# AT32UC3L064 device description
Architecture: AVR32_UC3; Family: AVR UC3
Registers are 32-bit, read-write, reset 0x0 unless marked. A register's access mark holds for its fields unless they carry their own. Offsets are from the block's base; [hi:lo] are bit positions; lines under a group give offsets from that group; {n}, {i} and the like mark numbered series; 'fields as' and 'values as' point back to an identical list.

## SAU_HSB — Secure Access Unit
{0x0+4i} RTR[{i}] (i=0..15) access not given reset not defined
  [31:0] RTR — Remap Target Address for channel n
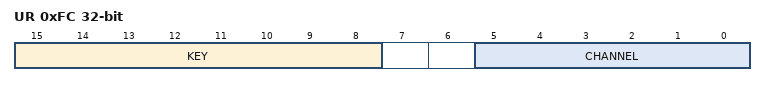
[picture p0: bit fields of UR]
0xFC UR wo reset not defined — Unlock Register
  [15:8] KEY — Unlock Key
  [5:0] CHANNEL — Channel number to unlock

## TWIM — Two-wire Master Interface
Instances: TWIM0 0xffff4400, TWIM1 0xffff4800
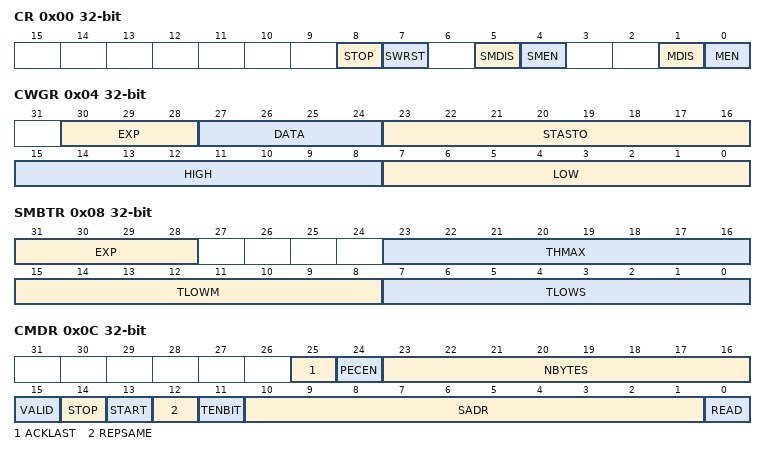
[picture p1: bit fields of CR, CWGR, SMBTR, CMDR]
0x00 CR wo
  [8] STOP, [7] SWRST, [5] SMDIS, [4] SMEN, [1] MDIS, [0] MEN
0x04 CWGR — Clock Waveform Generator
  [30:28] EXP, [27:24] DATA, [23:16] STASTO, [15:8] HIGH, [7:0] LOW
0x08 SMBTR — SMBus Time Out
  [31:28] EXP, [23:16] THMAX, [15:8] TLOWM, [7:0] TLOWS
0x0C CMDR — Command
  [25] ACKLAST, [24] PECEN, [23:16] NBYTES, [15] VALID, [14] STOP, [13] START, [12] REPSAME, [11] TENBIT, [10:1] SADR, [0] READ
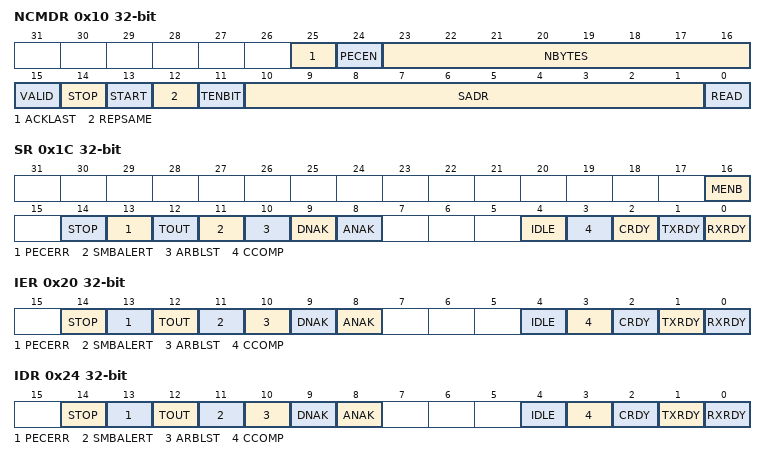
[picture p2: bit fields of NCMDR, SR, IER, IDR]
0x10 NCMDR — Next Command
  fields as CMDR
0x14 RHR ro — Receive Holding Registre
  [7:0] RXDATA
0x18 THR wo — Transmit Holding Register
  [7:0] TXDATA
0x1C SR ro — Status Register
  [16] MENB, [14] STOP, [13] PECERR, [12] TOUT, [11] SMBALERT, [10] ARBLST, [9] DNAK, [8] ANAK, [4] IDLE, [3] CCOMP, [2] CRDY, [1] TXRDY, [0] RXRDY
0x20 IER wo — Interrupt Enable Register
  [14] STOP, [13] PECERR, [12] TOUT, [11] SMBALERT, [10] ARBLST, [9] DNAK, [8] ANAK, [4] IDLE, [3] CCOMP, [2] CRDY, [1] TXRDY, [0] RXRDY
0x24 IDR wo — Interrupt Disable Register
  fields as IER
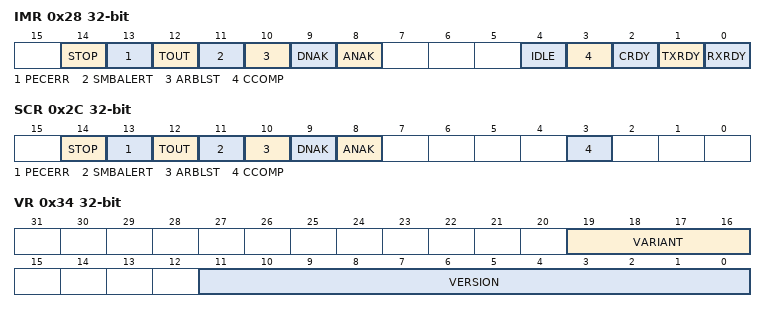
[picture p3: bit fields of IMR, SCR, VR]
0x28 IMR ro — Interrupt Mask Register
  fields as IER
0x2C SCR wo — Status Clear Register
  [14] STOP, [13] PECERR, [12] TOUT, [11] SMBALERT, [10] ARBLST, [9] DNAK, [8] ANAK, [3] CCOMP
0x30 PR ro — Parameter Register
0x34 VR ro — Version Register
  [19:16] VARIANT, [11:0] VERSION

## TWIS — Two-wire Slave Interface
Instances: TWIS0 0xffff4c00, TWIS1 0xffff5000
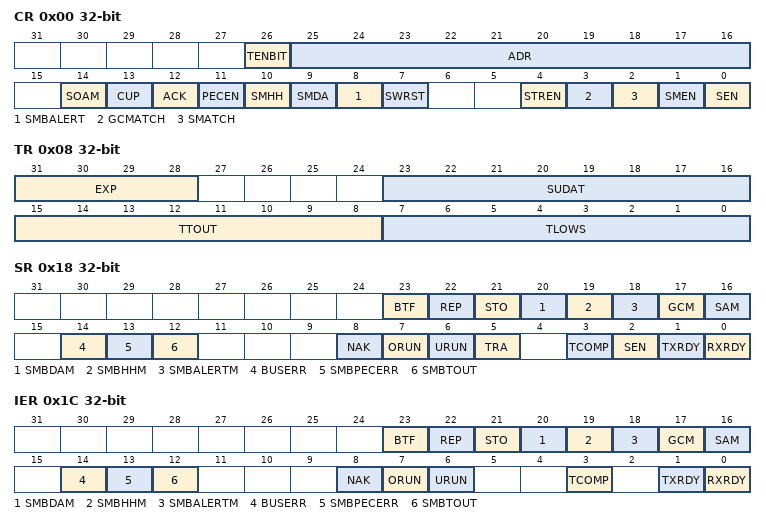
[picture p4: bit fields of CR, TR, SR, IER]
0x00 CR — Control Register
  [26] TENBIT, [25:16] ADR, [14] SOAM, [13] CUP, [12] ACK, [11] PECEN, [10] SMHH, [9] SMDA, [8] SMBALERT, [7] SWRST, [4] STREN, [3] GCMATCH, [2] SMATCH, [1] SMEN, [0] SEN
0x04 NBYTES
  [7:0] NBYTES
0x08 TR — Timing Register
  [31:28] EXP, [23:16] SUDAT, [15:8] TTOUT, [7:0] TLOWS
0x0C RHR ro — Receive Holding Registre
  [7:0] RXDATA
0x10 THR wo — Transmit Holding Register
  [7:0] TXDATA
0x14 PECR ro — Packet Error Check Register
  [7:0] PEC
0x18 SR ro — Status Register
  [23] BTF, [22] REP, [21] STO, [20] SMBDAM, [19] SMBHHM, [18] SMBALERTM, [17] GCM, [16] SAM, [14] BUSERR, [13] SMBPECERR, [12] SMBTOUT, [8] NAK, [7] ORUN, [6] URUN, [5] TRA, [3] TCOMP, [2] SEN, [1] TXRDY, [0] RXRDY
0x1C IER wo — Interrupt Enable Register
  [23] BTF, [22] REP, [21] STO, [20] SMBDAM, [19] SMBHHM, [18] SMBALERTM, [17] GCM, [16] SAM, [14] BUSERR, [13] SMBPECERR, [12] SMBTOUT, [8] NAK, [7] ORUN, [6] URUN, [3] TCOMP, [1] TXRDY, [0] RXRDY
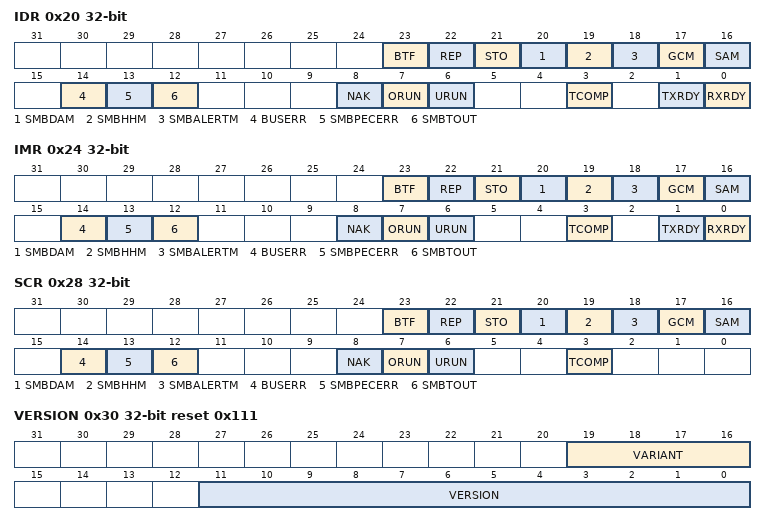
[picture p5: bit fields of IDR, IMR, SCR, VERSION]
0x20 IDR wo — Interrupt Disable Register
  fields as IER
0x24 IMR ro — Interrupt Mask Register
  fields as IER
0x28 SCR — Status Clear Register
  [23] BTF, [22] REP, [21] STO, [20] SMBDAM, [19] SMBHHM, [18] SMBALERTM, [17] GCM, [16] SAM, [14] BUSERR, [13] SMBPECERR, [12] SMBTOUT, [8] NAK, [7] ORUN, [6] URUN, [3] TCOMP
0x2C PR ro — Parameter Register
0x30 VERSION ro reset 0x111
  [19:16] VARIANT, [11:0] VERSION

## WDT — Watchdog Timer
Instances: WDT 0xffff2000
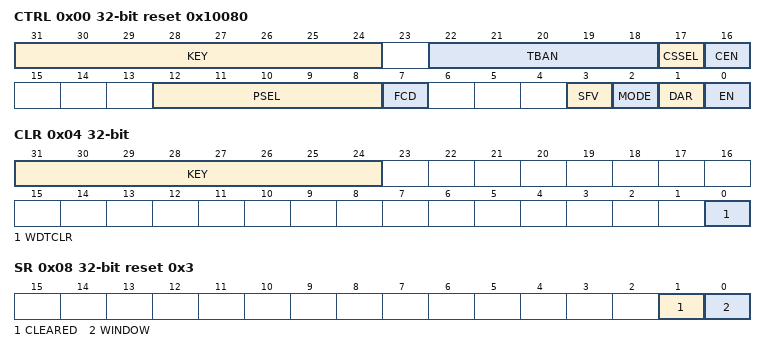
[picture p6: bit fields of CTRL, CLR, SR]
0x00 CTRL reset 0x10080 — WDT Control
  [31:24] KEY
  [22:18] TBAN — TBAN Prescale Select
  [17] CSSEL — Clock Source Selection
  [16] CEN — Clock Enable
  [12:8] PSEL — Timeout Prescale Select
  [7] FCD — WDT Fuse Calibration Done
  [3] SFV — WDT Store Final Value
  [2] MODE — WDT Mode
  [1] DAR — WDT Disable After Reset
  [0] EN — WDT Enable
0x04 CLR wo — WDT Clear
  [31:24] KEY
  [0] WDTCLR — Clear WDT counter
0x08 SR ro reset 0x3 — WDT Stastus
  [1] CLEARED — WDT cleared
  [0] WINDOW — WDT in window
0x3FC VERSION ro reset not defined — WDT Version

## GPIO_LOCAL — Local Bus Mapped GPIO Registers
Instances: GPIO_LOCAL 0x40000000
Parameters: PORT_LENGTH=AVR32_GPIO_PORT_LENGTH
{0x0+0x100*i} port[{i}] (i=0..63) group
  0x40 ODERW wo reset not defined — Output Driver Enable Register - Write
  0x44 ODERS wo reset not defined — Output Driver Enable Register - Set
  0x48 ODERC wo reset not defined — Output Driver Enable Register - Clear
  0x4C ODERT wo reset not defined — Output Driver Enable Register - Toggle
  0x50 OVRW wo reset not defined — Output Value Register - Write
  0x54 OVRS wo reset not defined — Output Value Register - Set
  0x58 OVRC wo reset not defined — Output Value Register - Clear
  0x5C OVRT wo reset not defined — Output Value Register - Toggle
  0x60 PVR ro reset not defined — Pin Value Register

## USERPAGE_FUSES — Fuses
Instances: USERPAGE_FUSES 0x80800000
0x00 USERPAGE_WORD_0 reset 0xFFFFFFFF
  [0] WDTAUTO — Watch dog timer auto enable/disable at startup
    0=WDT_ENABLE (WDT is automatically enabled at startup); 1=WDT_DISABLE (WDT is not automatically enabled at startup)
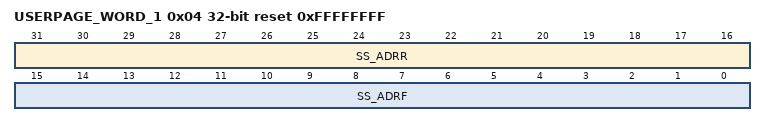
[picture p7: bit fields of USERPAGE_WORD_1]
0x04 USERPAGE_WORD_1 reset 0xFFFFFFFF
  [31:16] SS_ADRR — Size of the CPU RAM controlled by the Secure State
  [15:0] SS_ADRF — Size of the Flash controlled by the Secure State

## FLASH_FUSES — Fuses
Instances: FLASH_FUSES 0xFFFE0000 in fuses
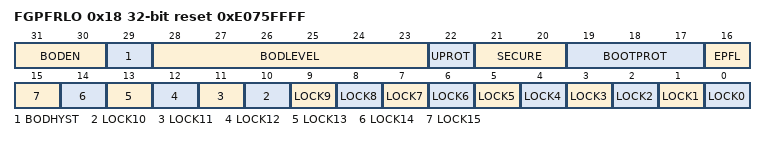
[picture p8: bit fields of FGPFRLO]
0x18 FGPFRLO reset 0xE075FFFF — Flash Controller General Purpose Fuse Register Low
  [31:30] BODEN — Brownout detector enable
    0=BOD_DISABLED; 1=BOD_ENABLED_RESET_ENABLED (BOD enabled, BOD reset enabled); 2=BOD_ENABLED_RESET_DISABLED (BOD enabled, BOD reset disabled); 3=BOD_DISABLED2
  [29] BODHYST — Brownout detector hysteresis
    0=BODHYST_DISABLED (Disabled); 1=BODHYST_ENABLED (Enabled)
  [28:23] BODLEVEL — Brownout detector trigger level
    0=BOD_LEVEL_OFF; 31=BOD_LEVEL_1V56 (BOD Level 1.56V); 39=BOD_LEVEL_1V65 (BOD Level 1.65V)
  [22] UPROT — JTAG user protection
    1=UPROT_ENABLE (Enable JTAG user protection); 0=UPROT_DISABLE (Disable JTAG user protection)
  [21:20] SECURE — Secure State
    0=SSDIS (Secure state disabled); 1=SSEN_SSDDIS (Secure enabled, secure state debug enabled); 2=SSEN_SSDEN (Secure enabled, secure state debug disabled); 3=SSDIS (Secure state disabled)
  [19:17] BOOTPROT — Bootloader protection
    0=BOOTAREA_32KB (Boot area: 32 Kbyte); 1=BOOTAREA_16KB (Boot area: 16 Kbyte); 2=BOOTAREA_8KB (Boot area: 8 Kbyte); 3=BOOTAREA_4KB (Boot area: 4 Kbyte); 4=BOOTAREA_2KB (Boot area: 2 Kbyte); 5=BOOTAREA_1KB (Boot area: 1 Kbyte); 6=BOOTAREA_512B (Boot area: 512 bytes); 7=BOOTAREA_0B (Boot area: 0 byte)
  [16] EPFL — External privileged fetch lock
    0=EPFL_LOCK (External privileged fetch locked); 1=EPFL_NO_LOCK (External privileged fetch not locked)
  [n] LOCK{n} (n=0..15)
